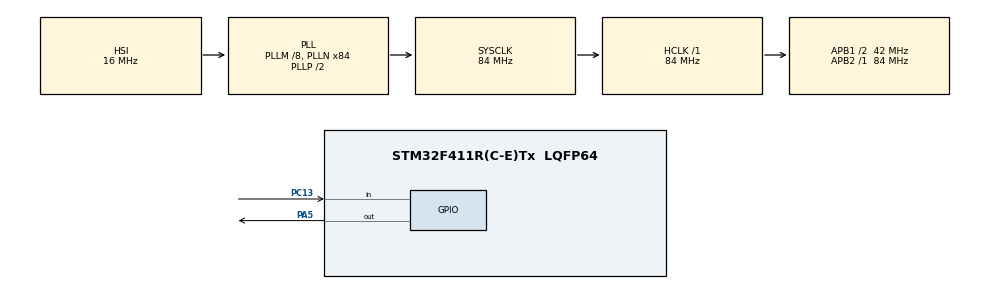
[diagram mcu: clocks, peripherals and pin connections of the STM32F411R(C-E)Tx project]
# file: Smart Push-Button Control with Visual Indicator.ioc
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Mcu.Family=STM32F4
Mcu.Name=STM32F411R(C-E)Tx
Mcu.Package=LQFP64
NVIC.PriorityGroup=NVIC_PRIORITYGROUP_4
PA5.Signal=GPIO_Output
PC13-ANTI_TAMP.Signal=GPIO_Input
ProjectManager.HeapSize=0x200
ProjectManager.StackSize=0x400
ProjectManager.TargetToolchain=STM32CubeIDE
RCC.48MHZClocksFreq_Value=42000000
RCC.AHBFreq_Value=84000000
RCC.APB1CLKDivider=RCC_HCLK_DIV2
RCC.APB1Freq_Value=42000000
RCC.APB1TimFreq_Value=84000000
RCC.APB2Freq_Value=84000000
RCC.APB2TimFreq_Value=84000000
RCC.CortexFreq_Value=84000000
RCC.HCLKFreq_Value=84000000
RCC.HSE_VALUE=25000000
RCC.HSI_VALUE=16000000
RCC.LSE_VALUE=32768
RCC.PLLM=8
RCC.PLLN=84
RCC.SYSCLKFreq_VALUE=84000000
RCC.SYSCLKSource=RCC_SYSCLKSOURCE_PLLCLK
RCC.VCOOutputFreq_Value=168000000
board=custom

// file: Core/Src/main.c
/* USER CODE BEGIN Header */
/**
 ******************************************************************************
 * @file           : main.c
 * @brief          : Main program body
 ******************************************************************************
 * @attention
 *
 * Copyright (c) 2025 STMicroelectronics.
 * All rights reserved.
 *
 * This software is licensed under terms that can be found in the LICENSE file
 * in the root directory of this software component.
 * If no LICENSE file comes with this software, it is provided AS-IS.
 *
 ******************************************************************************
 */
/* USER CODE END Header */
#include "main.h"
#include "gpio.h"

/* USER CODE BEGIN Includes */
#include "gpio_config.h"
/* USER CODE END Includes */

void SystemClock_Config(void);

/* USER CODE BEGIN 0 */
#define LONG_PRESS_TIME 2000   // 2 seconds
#define DEBOUNCE_TIME 100       // 50 ms //i need to increase it
/* USER CODE END 0 */

int main(void)
{
    HAL_Init();
    SystemClock_Config();
    GPIO_Init();

    uint8_t last_state = 0;
    uint32_t press_start = 0;

    while(1)
    {
        uint8_t state = Button_Read();

        if(state && !last_state)       // Button pressed
        {
            press_start = 0;
        }

        if(state)                       // Button held
        {
            press_start++;
            if(press_start == LONG_PRESS_TIME)
            {
                LED_Blink(3, 150);     // Long press action
            }
        }

        if(!state && last_state)        // Button released
        {
            if(press_start < LONG_PRESS_TIME && press_start > DEBOUNCE_TIME)
            {
                LED_Toggle();           // Short press action
            }
            press_start = 0;
        }

        last_state = state;

        delay_ms(1); // ~1ms tick
    }
}

void SystemClock_Config(void)
{
	RCC_OscInitTypeDef RCC_OscInitStruct = {0};
	RCC_ClkInitTypeDef RCC_ClkInitStruct = {0};

	/** Configure the main internal regulator output voltage
	 */
	__HAL_RCC_PWR_CLK_ENABLE();
	__HAL_PWR_VOLTAGESCALING_CONFIG(PWR_REGULATOR_VOLTAGE_SCALE1);

	/** Initializes the RCC Oscillators according to the specified parameters
	 * in the RCC_OscInitTypeDef structure.
	 */
	RCC_OscInitStruct.OscillatorType = RCC_OSCILLATORTYPE_HSI;
	RCC_OscInitStruct.HSIState = RCC_HSI_ON;
	RCC_OscInitStruct.HSICalibrationValue = RCC_HSICALIBRATION_DEFAULT;
	RCC_OscInitStruct.PLL.PLLState = RCC_PLL_ON;
	RCC_OscInitStruct.PLL.PLLSource = RCC_PLLSOURCE_HSI;
	RCC_OscInitStruct.PLL.PLLM = 8;
	RCC_OscInitStruct.PLL.PLLN = 84;
	RCC_OscInitStruct.PLL.PLLP = RCC_PLLP_DIV2;
	RCC_OscInitStruct.PLL.PLLQ = 4;
	if (HAL_RCC_OscConfig(&RCC_OscInitStruct) != HAL_OK)
	{
		Error_Handler();
	}

	/** Initializes the CPU, AHB and APB buses clocks
	 */
	RCC_ClkInitStruct.ClockType = RCC_CLOCKTYPE_HCLK|RCC_CLOCKTYPE_SYSCLK
			|RCC_CLOCKTYPE_PCLK1|RCC_CLOCKTYPE_PCLK2;
	RCC_ClkInitStruct.SYSCLKSource = RCC_SYSCLKSOURCE_PLLCLK;
	RCC_ClkInitStruct.AHBCLKDivider = RCC_SYSCLK_DIV1;
	RCC_ClkInitStruct.APB1CLKDivider = RCC_HCLK_DIV2;
	RCC_ClkInitStruct.APB2CLKDivider = RCC_HCLK_DIV1;

	if (HAL_RCC_ClockConfig(&RCC_ClkInitStruct, FLASH_LATENCY_2) != HAL_OK)
	{
		Error_Handler();
	}
}

void Error_Handler(void)
{
	__disable_irq();
	while (1)
	{
	}
}
